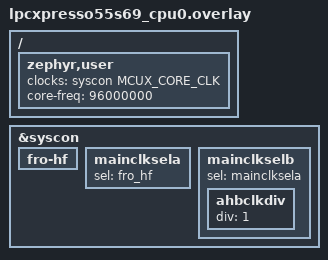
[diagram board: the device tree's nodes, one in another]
/*
 * Copyright 2023 NXP
 *
 * SPDX-License-Identifier: Apache-2.0
 *
 */

#include <zephyr/dt-bindings/clock/mcux_lpc_syscon_clock.h>

/ {
	zephyr,user {
		clocks = <&syscon MCUX_CORE_CLK>;
		core-freq = <96000000>;
	};
};

/* Setup core clock for 96MHz operation */
&syscon {
	/* Enable FRO HF */
	fro-hf {
		status = "okay";
	};

	/* Route FROHF to main clock */
	mainclksela {
		status = "okay";
		sel = <&fro_hf>;
	};

	mainclkselb {
		status = "okay";
		sel = <&mainclksela>;
		/* AHB clk div sets main system clock, which will be 96MHz */
		ahbclkdiv {
			status = "okay";
			div = <1>;
		};
	};
};
